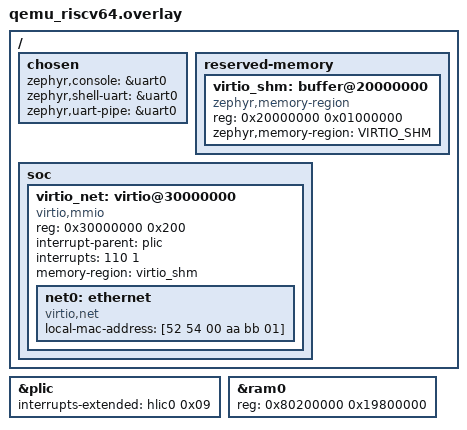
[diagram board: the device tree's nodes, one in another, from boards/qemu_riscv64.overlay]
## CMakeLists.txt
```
# SPDX-License-Identifier: Apache-2.0

cmake_minimum_required(VERSION 3.20.0)

find_package(Zephyr)
project(birtio-qemu)

zephyr_include_directories(src)
target_sources(app PRIVATE src/main.c src/virtio_shm_alloc.c)
```

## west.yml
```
manifest:
  remotes:
    - name: zephyrproject-rtos
      url-base: https://github.com/zephyrproject-rtos
  projects:
    - name: zephyr
      remote: zephyrproject-rtos
      revision: v2.5.0
      import: true
  self:
    path: birtio
```

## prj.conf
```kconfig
CONFIG_BUILD_OUTPUT_BIN=y

# Networking
CONFIG_NETWORKING=y
CONFIG_NET_IPV4=y
CONFIG_NET_L2_ETHERNET=y
CONFIG_NET_ARP=y
CONFIG_NET_SOCKETS=y
CONFIG_NET_TCP=y

# Console and shell
CONFIG_SERIAL=y
CONFIG_CONSOLE=y
CONFIG_UART_CONSOLE=y
# CONFIG_SHELL=y
# CONFIG_NET_SHELL=y
# CONFIG_THREAD_MONITOR=y

# VirtIO
CONFIG_VIRTIO=y
CONFIG_VIRTIO_MMIO=y
CONFIG_ETH_VIRTIO_NET=y
CONFIG_SLIP=n
CONFIG_ETH_LOWRISC=n

# IP
CONFIG_NET_CONFIG_SETTINGS=y
CONFIG_NET_CONFIG_MY_IPV4_ADDR="192.168.42.16"
CONFIG_NET_CONFIG_MY_IPV4_NETMASK="255.255.255.0"
CONFIG_NET_CONFIG_PEER_IPV4_ADDR="192.168.42.1"

# Entropy
CONFIG_ENTROPY_GENERATOR=y
CONFIG_TEST_RANDOM_GENERATOR=y

# Buffers
CONFIG_NET_PKT_RX_COUNT=32
CONFIG_NET_PKT_TX_COUNT=16
CONFIG_NET_BUF_RX_COUNT=64
CONFIG_NET_BUF_TX_COUNT=32
CONFIG_HEAP_MEM_POOL_SIZE=32768

# ── Timer resolution ───────────────────────────────────────────
# Increase tick rate for better RTT resolution.
# 1000 Hz = 1000 us/tick.  Try 1000000 (1 us) if your board supports it.
CONFIG_SYS_CLOCK_TICKS_PER_SEC=1000
CONFIG_NET_SOCKETS_POLL_MAX=8

# Default settings for M-Mode
# CONFIG_RISCV_MACHINE_TIMER=y
# CONFIG_RISCV_SUPERVISOR_TIMER=n

# Supervisor mode (comment the configs below to enable S-Mode)
CONFIG_RISCV_SBI_BOOT=y
CONFIG_RISCV_S_MODE=y
CONFIG_RISCV_SUPERVISOR_TIMER=y
CONFIG_RISCV_MACHINE_TIMER=n

# enable the virtio shared memory allocator
CONFIG_VIRTIO_SHM_ALLOC=y
CONFIG_RISCV_PMP=n

# Subir prioridad de los threads de red
CONFIG_NET_RX_STACK_SIZE=4096
CONFIG_NET_TX_STACK_SIZE=4096
CONFIG_NET_TC_RX_COUNT=1
CONFIG_NET_TC_TX_COUNT=1
```

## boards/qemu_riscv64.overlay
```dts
/*
 * SPDX-License-Identifier: Apache-2.0
 * Overlay: virtio shared memory for Bao hypervisor
 */

/ {
	chosen {
        zephyr,console = &uart0;
        zephyr,shell-uart = &uart0; 
        zephyr,uart-pipe = &uart0;
    };

	reserved-memory {
		#address-cells = <1>;
		#size-cells = <1>;
		ranges;

		virtio_shm: buffer@20000000 {
			compatible = "zephyr,memory-region";
			reg = <0x20000000 0x01000000>;
			zephyr,memory-region = "VIRTIO_SHM";
		};
	};

	soc {
		virtio_net: virtio@30000000 {
			compatible = "virtio,mmio";
			reg = <0x30000000 0x200>;
			interrupt-parent = <&plic>;
			interrupts = <110 1>;
			status = "okay";
			memory-region = <&virtio_shm>;

			net0: ethernet {
				compatible = "virtio,net";
				status = "okay";
				local-mac-address = [52 54 00 aa bb 01];
			};
		};
	};
};

&plic {
	interrupts-extended = <&hlic0 0x09>;
};

&ram0 {
	reg = <0x80200000 0x19800000>;
};
```

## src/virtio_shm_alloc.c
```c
#include "virtio_shm_alloc.h"

static uintptr_t shm_base;
static uintptr_t shm_offset;
static size_t shm_total;

void virtio_shm_init(uintptr_t base, size_t size)
{
    shm_base = base;
    shm_offset = 0;
    shm_total = size;
}

void *virtio_shm_alloc(size_t size, size_t align)
{
    uintptr_t current = shm_base + shm_offset;
    uintptr_t aligned = (current + align - 1) & ~(align - 1);
    size_t padding = aligned - current;

    if (shm_offset + padding + size > shm_total) {
        return NULL;
    }

    shm_offset += padding + size;
    return (void *)aligned;
}

void virtio_shm_free(void *ptr)
{
    (void)ptr;
}
```
